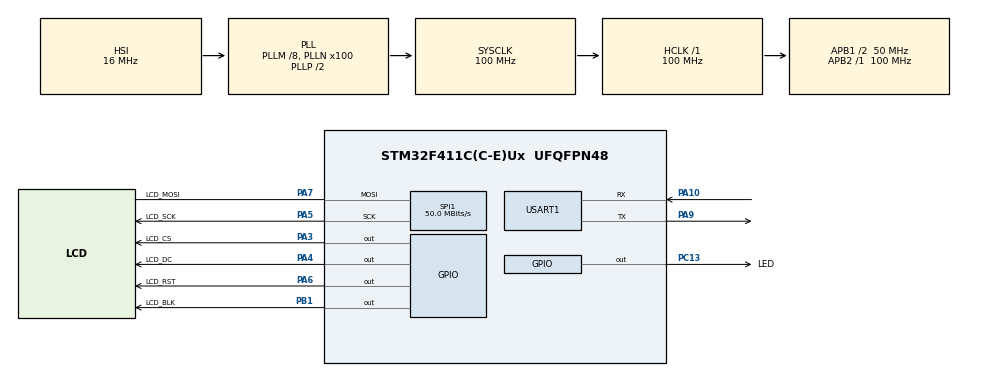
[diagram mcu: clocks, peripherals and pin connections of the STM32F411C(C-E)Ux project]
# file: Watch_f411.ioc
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Mcu.Family=STM32F4
Mcu.Name=STM32F411C(C-E)Ux
Mcu.Package=UFQFPN48
NVIC.PriorityGroup=NVIC_PRIORITYGROUP_4
NVIC.TIM4_IRQn=true\:0\:0\:false\:false\:true\:true\:true\:true
PA10.Mode=Asynchronous
PA10.Signal=USART1_RX
PA13.Mode=Serial_Wire
PA13.Signal=SYS_JTMS-SWDIO
PA14.Mode=Serial_Wire
PA14.Signal=SYS_JTCK-SWCLK
PA3.GPIO_Label=LCD_CS
PA3.Signal=GPIO_Output
PA4.GPIO_Label=LCD_DC
PA4.Signal=GPIO_Output
PA5.GPIO_Label=LCD_SCK
PA5.Mode=Simplex_Bidirectional_Master
PA5.Signal=SPI1_SCK
PA6.GPIO_Label=LCD_RST
PA6.Signal=GPIO_Output
PA7.GPIO_Label=LCD_MOSI
PA7.Mode=Simplex_Bidirectional_Master
PA7.Signal=SPI1_MOSI
PA9.Mode=Asynchronous
PA9.Signal=USART1_TX
PB1.GPIO_Label=LCD_BLK
PB1.Signal=GPIO_Output
PC13-ANTI_TAMP.GPIO_Label=LED
PC13-ANTI_TAMP.PinState=GPIO_PIN_RESET
PC13-ANTI_TAMP.Signal=GPIO_Output
PH0\ -\ OSC_IN.Mode=HSE-External-Oscillator
PH0\ -\ OSC_IN.Signal=RCC_OSC_IN
PH1\ -\ OSC_OUT.Mode=HSE-External-Oscillator
PH1\ -\ OSC_OUT.Signal=RCC_OSC_OUT
ProjectManager.HeapSize=0x1000
ProjectManager.StackSize=0x1000
ProjectManager.TargetToolchain=CMake
RCC.48MHZClocksFreq_Value=50000000
RCC.AHBFreq_Value=100000000
RCC.APB1CLKDivider=RCC_HCLK_DIV2
RCC.APB1Freq_Value=50000000
RCC.APB1TimFreq_Value=100000000
RCC.APB2Freq_Value=100000000
RCC.APB2TimFreq_Value=100000000
RCC.CortexFreq_Value=100000000
RCC.HCLKFreq_Value=100000000
RCC.HSE_VALUE=25000000
RCC.HSI_VALUE=16000000
RCC.LSE_VALUE=32768
RCC.PLLM=8
RCC.PLLN=100
RCC.SYSCLKFreq_VALUE=100000000
RCC.SYSCLKSource=RCC_SYSCLKSOURCE_PLLCLK
RCC.VCOOutputFreq_Value=200000000
SPI1.CalculateBaudRate=50.0 MBits/s
SPI1.Direction=SPI_DIRECTION_1LINE
SPI1.Mode=SPI_MODE_MASTER
SPI1.VirtualType=VM_MASTER
TIM4.AutoReloadPreload=TIM_AUTORELOAD_PRELOAD_ENABLE
TIM4.Period=9
TIM4.Prescaler=9999
USART1.VirtualMode=VM_ASYNC
VP_TIM4_VS_ClockSourceINT.Mode=Internal
board=custom

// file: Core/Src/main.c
/* USER CODE BEGIN Header */
/**
  ******************************************************************************
  * @file           : main.c
  * @brief          : Main program body
  ******************************************************************************
  * @attention
  *
  * Copyright (c) 2026 STMicroelectronics.
  * All rights reserved.
  *
  * This software is licensed under terms that can be found in the LICENSE file
  * in the root directory of this software component.
  * If no LICENSE file comes with this software, it is provided AS-IS.
  *
  ******************************************************************************
  */
/* USER CODE END Header */
#include "main.h"
#include "spi.h"
#include "tim.h"
#include "usart.h"
#include "gpio.h"

/* USER CODE BEGIN Includes */
#include "headfile.h"
/* USER CODE END Includes */

void SystemClock_Config(void);
/* USER CODE BEGIN PFP */
int _write(int fd, char *ptr, int len)
{
    HAL_UART_Transmit(&huart1, (uint8_t*)ptr, len, HAL_MAX_DELAY);
    return len;
}
extern CST816_Info CST816_Instance;
lv_ui guider_ui;
/* USER CODE END PFP */

int main(void)
{

  /* MCU Configuration--------------------------------------------------------*/

  /* Reset of all peripherals, Initializes the Flash interface and the Systick. */
  HAL_Init();

  /* Configure the system clock */
  SystemClock_Config();

  /* Initialize all configured peripherals */
  MX_GPIO_Init();
  MX_TIM4_Init();
  MX_SPI1_Init();
  MX_USART1_UART_Init();
  /* USER CODE BEGIN 2 */
  HAL_TIM_Base_Start_IT(&htim4);
  lv_init();
  lv_port_disp_init();
  lv_port_indev_init();

  setup_ui(&guider_ui);
  events_init(&guider_ui);
  /* USER CODE END 2 */

  /* Infinite loop */
  /* USER CODE BEGIN WHILE */
  while (1)
  {
    delay_ms(5);
    lv_timer_handler();
    /* USER CODE END WHILE */

  }
}

void SystemClock_Config(void)
{
  RCC_OscInitTypeDef RCC_OscInitStruct = {0};
  RCC_ClkInitTypeDef RCC_ClkInitStruct = {0};

  /** Configure the main internal regulator output voltage
  */
  __HAL_RCC_PWR_CLK_ENABLE();
  __HAL_PWR_VOLTAGESCALING_CONFIG(PWR_REGULATOR_VOLTAGE_SCALE1);

  /** Initializes the RCC Oscillators according to the specified parameters
  * in the RCC_OscInitTypeDef structure.
  */
  RCC_OscInitStruct.OscillatorType = RCC_OSCILLATORTYPE_HSI;
  RCC_OscInitStruct.HSIState = RCC_HSI_ON;
  RCC_OscInitStruct.HSICalibrationValue = RCC_HSICALIBRATION_DEFAULT;
  RCC_OscInitStruct.PLL.PLLState = RCC_PLL_ON;
  RCC_OscInitStruct.PLL.PLLSource = RCC_PLLSOURCE_HSI;
  RCC_OscInitStruct.PLL.PLLM = 8;
  RCC_OscInitStruct.PLL.PLLN = 100;
  RCC_OscInitStruct.PLL.PLLP = RCC_PLLP_DIV2;
  RCC_OscInitStruct.PLL.PLLQ = 4;
  if (HAL_RCC_OscConfig(&RCC_OscInitStruct) != HAL_OK)
  {
    Error_Handler();
  }

  /** Initializes the CPU, AHB and APB buses clocks
  */
  RCC_ClkInitStruct.ClockType = RCC_CLOCKTYPE_HCLK|RCC_CLOCKTYPE_SYSCLK
                              |RCC_CLOCKTYPE_PCLK1|RCC_CLOCKTYPE_PCLK2;
  RCC_ClkInitStruct.SYSCLKSource = RCC_SYSCLKSOURCE_PLLCLK;
  RCC_ClkInitStruct.AHBCLKDivider = RCC_SYSCLK_DIV1;
  RCC_ClkInitStruct.APB1CLKDivider = RCC_HCLK_DIV2;
  RCC_ClkInitStruct.APB2CLKDivider = RCC_HCLK_DIV1;

  if (HAL_RCC_ClockConfig(&RCC_ClkInitStruct, FLASH_LATENCY_3) != HAL_OK)
  {
    Error_Handler();
  }
}

void Error_Handler(void)
{
  __disable_irq();
  while (1)
  {
  }
}
